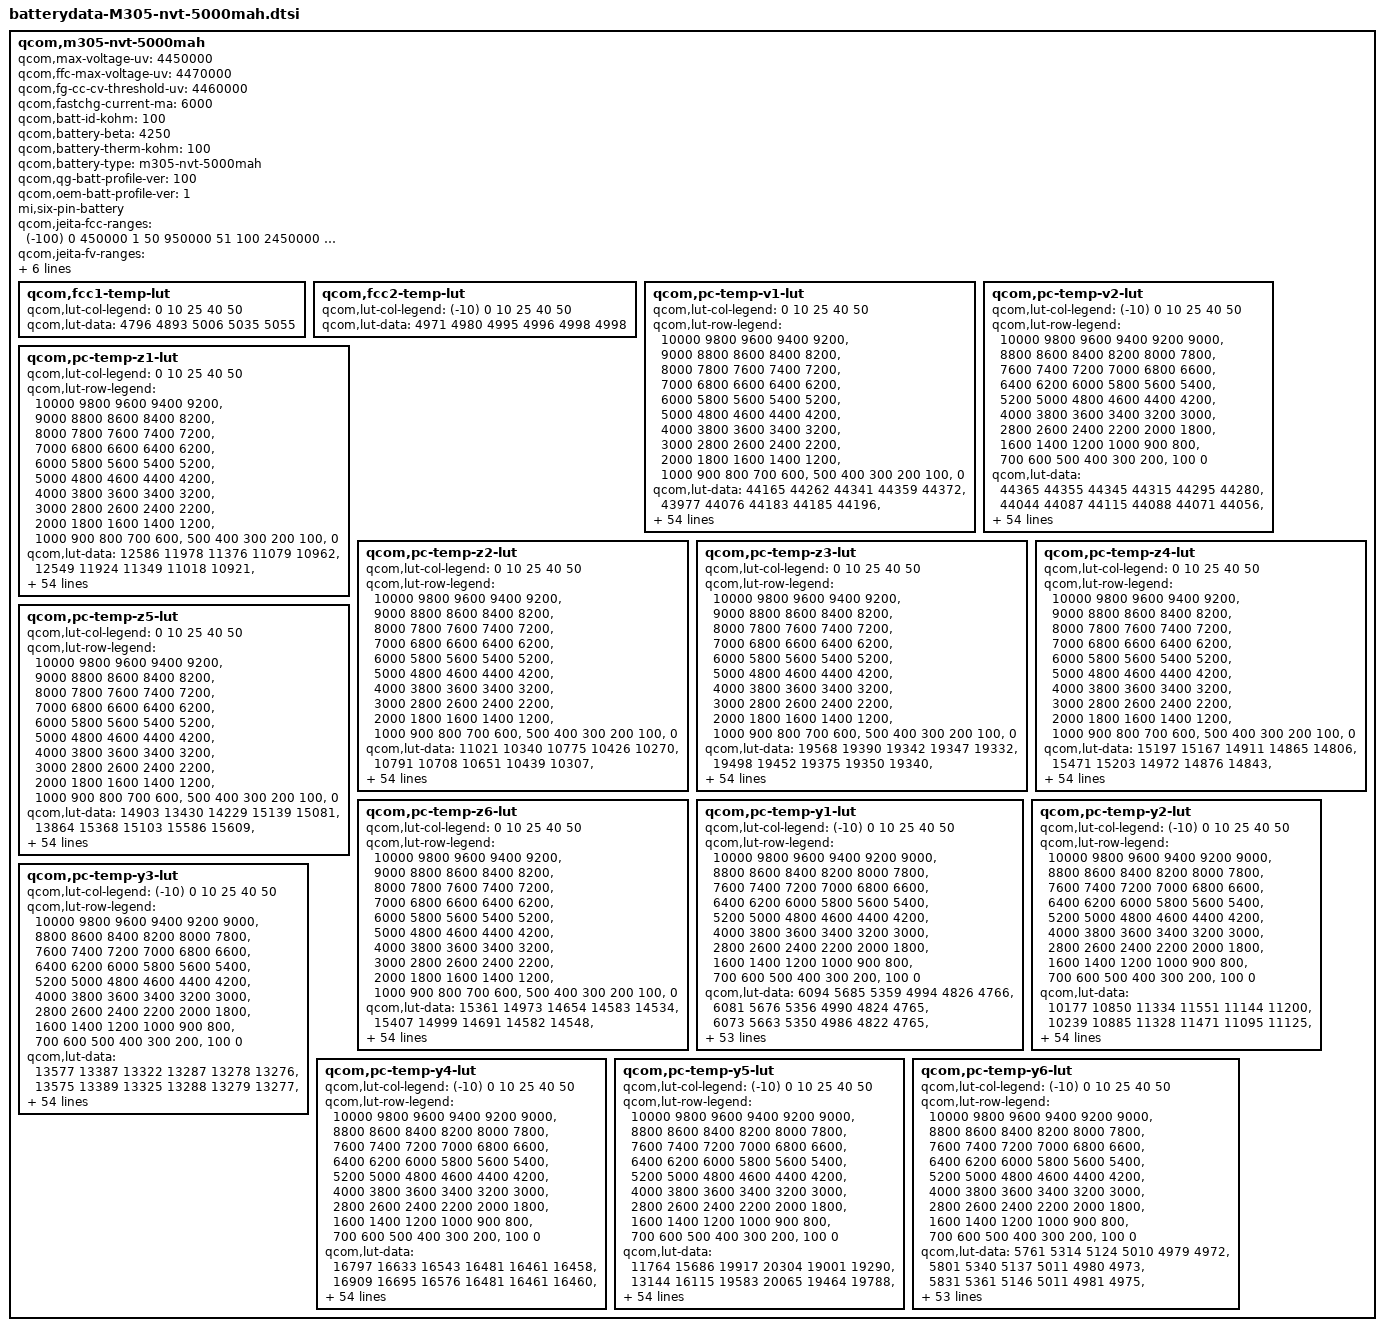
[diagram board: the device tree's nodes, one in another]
/*
 * Copyright (c) 2019, The Linux Foundation. All rights reserved.
 * Copyright (C) 2021 XiaoMi, Inc.
 *
 * This program is free software; you can redistribute it and/or modify
 * it under the terms of the GNU General Public License version 2 and
 * only version 2 as published by the Free Software Foundation.
 *
 * This program is distributed in the hope that it will be useful,
 * but WITHOUT ANY WARRANTY; without even the implied warranty of
 * MERCHANTABILITY or FITNESS FOR A PARTICULAR PURPOSE.  See the
 * GNU General Public License for more details.
 */
/* 4622819_LC_M700_ATL_5160mAH_PM7150B_averaged_Master_May26th2020 */

 qcom,m305-nvt-5000mah {
	qcom,max-voltage-uv = <4450000>;
	qcom,ffc-max-voltage-uv = <4470000>;
	qcom,fg-cc-cv-threshold-uv = <4460000>;
	qcom,fastchg-current-ma = <6000>;
	qcom,batt-id-kohm = <100>;
	qcom,battery-beta = <4250>;
	qcom,battery-therm-kohm = <100>;
	qcom,battery-type = "m305-nvt-5000mah";
	qcom,qg-batt-profile-ver = <100>;
	qcom,oem-batt-profile-ver = <1>;
	mi,six-pin-battery;

	qcom,jeita-fcc-ranges = <(-100)  0   450000
                                1   50   950000
				51  100  2450000
				101 150  3900000
				151 480  6000000
				481 580  2450000>;

	qcom,jeita-fv-ranges = <(-100)   0   4450000
                                1   50   4450000
				51  100  4450000
				101 150  4450000
				151 480  4470000
				481 580  4100000>;

	/* COOL = 15 degc, WARM = 48 degC */
	qcom,jeita-soft-thresholds = <0x4621 0x1de6>;
	/* COLD = -10 degC, HOT = 58 degC*/
	qcom,jeita-hard-thresholds = <0x6226 0x15f7>;
	/* COOL hys = 18 degC, WARM hys = 45 degC */
	qcom,jeita-soft-hys-thresholds = <0x4206 0x20b8>;
	qcom,jeita-soft-fcc-ua = <3900000 2450000>;
	qcom,jeita-soft-fv-uv = <4450000 4100000>;

	qcom,fcc1-temp-lut {
		qcom,lut-col-legend = <0 10 25 40 50>;
		qcom,lut-data = <4796 4893 5006 5035 5055>;
	};

	qcom,fcc2-temp-lut {
		qcom,lut-col-legend = <(-10) 0 10 25 40 50>;
		qcom,lut-data = <4971 4980 4995 4996 4998 4998>;
	};

	qcom,pc-temp-v1-lut {
		qcom,lut-col-legend = <0 10 25 40 50>;
		qcom,lut-row-legend = <10000 9800 9600 9400 9200>,
			<9000 8800 8600 8400 8200>,
			<8000 7800 7600 7400 7200>,
			<7000 6800 6600 6400 6200>,
			<6000 5800 5600 5400 5200>,
			<5000 4800 4600 4400 4200>,
			<4000 3800 3600 3400 3200>,
			<3000 2800 2600 2400 2200>,
			<2000 1800 1600 1400 1200>,
			<1000 900 800 700 600>,
			<500 400 300 200 100>,
			<0>;
		qcom,lut-data = <44165 44262 44341 44359 44372>,
			<43977 44076 44183 44185 44196>,
			<43767 43881 43986 44002 44014>,
			<43547 43680 43788 43811 43824>,
			<43319 43468 43583 43612 43623>,
			<43082 43240 43367 43401 43411>,
			<42843 43001 43137 43176 43190>,
			<42602 42761 42895 42936 42957>,
			<42360 42516 42651 42692 42718>,
			<42123 42271 42403 42446 42475>,
			<41889 42031 42157 42200 42227>,
			<41659 41793 41916 41959 41984>,
			<41434 41562 41677 41720 41741>,
			<41214 41334 41443 41485 41502>,
			<41001 41114 41214 41254 41270>,
			<40798 40907 40991 41028 41043>,
			<40597 40707 40778 40810 40826>,
			<40390 40509 40572 40600 40617>,
			<40184 40318 40375 40399 40416>,
			<39991 40120 40193 40218 40230>,
			<39821 39887 39993 40028 40040>,
			<39648 39616 39726 39782 39804>,
			<39434 39375 39434 39496 39524>,
			<39178 39178 39227 39276 39298>,
			<38972 39009 39078 39120 39138>,
			<38837 38884 38950 38986 39002>,
			<38731 38790 38833 38854 38867>,
			<38648 38703 38728 38732 38738>,
			<38583 38616 38626 38622 38623>,
			<38524 38534 38526 38523 38522>,
			<38467 38458 38435 38432 38430>,
			<38414 38385 38354 38348 38344>,
			<38364 38320 38281 38269 38265>,
			<38317 38265 38215 38196 38189>,
			<38274 38216 38158 38127 38117>,
			<38235 38170 38103 38061 38045>,
			<38200 38130 38051 37996 37969>,
			<38156 38085 37999 37932 37890>,
			<38080 38012 37928 37850 37798>,
			<37977 37909 37829 37744 37689>,
			<37864 37793 37715 37626 37567>,
			<37729 37661 37589 37499 37432>,
			<37577 37512 37446 37360 37286>,
			<37400 37337 37278 37200 37119>,
			<37272 37202 37146 37073 37003>,
			<37185 37128 37070 37004 36945>,
			<37164 37102 37050 36982 36925>,
			<37152 37085 37031 36966 36906>,
			<37111 37052 37002 36931 36862>,
			<36989 36928 36861 36765 36667>,
			<36621 36559 36490 36396 36294>,
			<36126 36069 36002 35912 35806>,
			<35490 35438 35371 35288 35176>,
			<34613 34564 34506 34428 34307>,
			<33199 33156 33113 33066 32918>,
			<30000 30000 30000 30000 30000>;
	};

	qcom,pc-temp-v2-lut {
		qcom,lut-col-legend = <(-10) 0 10 25 40 50>;
		qcom,lut-row-legend = <10000 9800 9600 9400 9200 9000>,
			<8800 8600 8400 8200 8000 7800>,
			<7600 7400 7200 7000 6800 6600>,
			<6400 6200 6000 5800 5600 5400>,
			<5200 5000 4800 4600 4400 4200>,
			<4000 3800 3600 3400 3200 3000>,
			<2800 2600 2400 2200 2000 1800>,
			<1600 1400 1200 1000 900 800>,
			<700 600 500 400 300 200>,
			<100 0>;
		qcom,lut-data = <44365 44355 44345 44315 44295 44280>,
			<44044 44087 44115 44088 44071 44056>,
			<43750 43835 43889 43865 43851 43836>,
			<43490 43603 43673 43649 43637 43623>,
			<43264 43392 43465 43439 43429 43417>,
			<43036 43175 43250 43223 43215 43204>,
			<42782 42934 43014 42989 42984 42974>,
			<42519 42683 42770 42746 42743 42735>,
			<42271 42432 42524 42501 42501 42494>,
			<42039 42180 42275 42254 42255 42249>,
			<41798 41931 42027 42008 42010 42005>,
			<41504 41688 41784 41767 41769 41764>,
			<41206 41450 41544 41528 41530 41525>,
			<41017 41222 41310 41293 41297 41291>,
			<40911 41004 41081 41062 41069 41062>,
			<40783 40792 40859 40839 40847 40839>,
			<40480 40593 40653 40627 40632 40626>,
			<40055 40395 40449 40421 40425 40420>,
			<39746 40159 40221 40219 40226 40223>,
			<39527 39867 39967 40025 40040 40039>,
			<39324 39584 39715 39815 39837 39839>,
			<39109 39346 39472 39555 39581 39584>,
			<38895 39130 39242 39281 39309 39315>,
			<38682 38939 39048 39071 39099 39106>,
			<38449 38768 38882 38903 38927 38934>,
			<38272 38612 38734 38757 38778 38785>,
			<38187 38471 38598 38626 38646 38653>,
			<38129 38341 38475 38510 38530 38535>,
			<38075 38216 38364 38403 38424 38425>,
			<38028 38087 38263 38304 38326 38323>,
			<37982 37987 38168 38212 38236 38230>,
			<37934 37929 38073 38125 38155 38149>,
			<37885 37886 37983 38044 38079 38072>,
			<37832 37848 37907 37970 37998 37988>,
			<37777 37818 37841 37903 37915 37896>,
			<37719 37782 37782 37833 37824 37797>,
			<37654 37736 37732 37746 37722 37683>,
			<37582 37676 37685 37653 37613 37562>,
			<37504 37600 37620 37563 37514 37458>,
			<37417 37495 37534 37477 37422 37368>,
			<37322 37375 37432 37383 37325 37272>,
			<37214 37244 37306 37269 37214 37156>,
			<37097 37108 37166 37144 37094 37030>,
			<36993 36988 37026 37006 36955 36888>,
			<36899 36888 36921 36917 36869 36811>,
			<36817 36798 36856 36878 36838 36783>,
			<36773 36736 36829 36863 36826 36768>,
			<36723 36655 36790 36839 36805 36744>,
			<36654 36548 36723 36788 36755 36676>,
			<36517 36367 36554 36604 36543 36397>,
			<36234 36077 36191 36189 36122 35956>,
			<35760 35632 35641 35647 35581 35391>,
			<35079 34982 34908 34939 34877 34643>,
			<34112 34036 33881 33943 33895 33601>,
			<32348 32327 32206 32341 32401 32072>,
			<27302 27182 27133 27142 28004 27330>;
	};

	qcom,pc-temp-z1-lut {
		qcom,lut-col-legend = <0 10 25 40 50>;
		qcom,lut-row-legend = <10000 9800 9600 9400 9200>,
			<9000 8800 8600 8400 8200>,
			<8000 7800 7600 7400 7200>,
			<7000 6800 6600 6400 6200>,
			<6000 5800 5600 5400 5200>,
			<5000 4800 4600 4400 4200>,
			<4000 3800 3600 3400 3200>,
			<3000 2800 2600 2400 2200>,
			<2000 1800 1600 1400 1200>,
			<1000 900 800 700 600>,
			<500 400 300 200 100>,
			<0>;
		qcom,lut-data = <12586 11978 11376 11079 10962>,
			<12549 11924 11349 11018 10921>,
			<12517 11890 11290 10993 10899>,
			<12487 11867 11256 10977 10884>,
			<12457 11845 11237 10965 10874>,
			<12428 11817 11220 10954 10866>,
			<12402 11788 11202 10944 10859>,
			<12377 11764 11185 10934 10852>,
			<12355 11744 11171 10927 10847>,
			<12342 11726 11160 10924 10845>,
			<12333 11707 11152 10921 10843>,
			<12324 11688 11148 10918 10842>,
			<12309 11681 11145 10916 10840>,
			<12292 11680 11143 10915 10839>,
			<12277 11679 11142 10914 10839>,
			<12255 11678 11141 10914 10839>,
			<12241 11675 11142 10914 10840>,
			<12242 11672 11142 10914 10841>,
			<12248 11670 11143 10914 10842>,
			<12255 11667 11144 10916 10844>,
			<12306 11667 11145 10917 10845>,
			<12358 11669 11146 10917 10846>,
			<12345 11670 11147 10917 10846>,
			<12285 11670 11148 10917 10846>,
			<12253 11670 11151 10918 10847>,
			<12255 11672 11154 10920 10850>,
			<12261 11680 11158 10922 10852>,
			<12265 11686 11162 10925 10854>,
			<12271 11687 11167 10928 10856>,
			<12276 11689 11171 10931 10859>,
			<12281 11692 11176 10934 10862>,
			<12288 11702 11182 10938 10865>,
			<12291 11712 11188 10942 10868>,
			<12297 11717 11193 10946 10871>,
			<12304 11722 11198 10950 10874>,
			<12306 11726 11204 10954 10878>,
			<12314 11732 11210 10958 10882>,
			<12318 11740 11216 10962 10885>,
			<12332 11749 11222 10966 10888>,
			<12352 11760 11229 10969 10891>,
			<12356 11766 11236 10973 10894>,
			<12352 11769 11243 10977 10897>,
			<12352 11773 11250 10980 10900>,
			<12362 11794 11255 10983 10901>,
			<12370 11817 11267 10988 10904>,
			<12393 11814 11276 10992 10905>,
			<12377 11813 11279 10990 10905>,
			<12399 11821 11279 10992 10907>,
			<12406 11821 11285 10994 10910>,
			<12418 11830 11295 10999 10913>,
			<12388 11832 11300 11005 10916>,
			<12401 11842 11313 11009 10922>,
			<12416 11850 11321 11017 10928>,
			<12454 11883 11337 11028 10939>,
			<12454 11883 11337 11028 10939>,
			<12454 11883 11337 11028 10939>;
	};

	qcom,pc-temp-z2-lut {
		qcom,lut-col-legend = <0 10 25 40 50>;
		qcom,lut-row-legend = <10000 9800 9600 9400 9200>,
			<9000 8800 8600 8400 8200>,
			<8000 7800 7600 7400 7200>,
			<7000 6800 6600 6400 6200>,
			<6000 5800 5600 5400 5200>,
			<5000 4800 4600 4400 4200>,
			<4000 3800 3600 3400 3200>,
			<3000 2800 2600 2400 2200>,
			<2000 1800 1600 1400 1200>,
			<1000 900 800 700 600>,
			<500 400 300 200 100>,
			<0>;
		qcom,lut-data = <11021 10340 10775 10426 10270>,
			<10791 10708 10651 10439 10307>,
			<10697 10779 10669 10457 10322>,
			<10637 10750 10670 10465 10328>,
			<10587 10710 10652 10462 10359>,
			<10546 10663 10627 10451 10409>,
			<10509 10607 10577 10428 10411>,
			<10472 10564 10508 10387 10359>,
			<10443 10528 10474 10363 10318>,
			<10426 10505 10454 10356 10307>,
			<10413 10499 10445 10352 10300>,
			<10408 10496 10449 10348 10298>,
			<10410 10497 10459 10336 10301>,
			<10414 10518 10471 10331 10303>,
			<10425 10552 10485 10339 10313>,
			<10456 10636 10497 10348 10327>,
			<10486 10802 10504 10349 10314>,
			<10501 10868 10511 10349 10253>,
			<10513 10758 10519 10347 10221>,
			<10520 10635 10535 10317 10231>,
			<10525 10634 10559 10288 10253>,
			<10530 10659 10613 10362 10306>,
			<10534 10671 10681 10555 10416>,
			<10540 10645 10684 10616 10463>,
			<10544 10608 10609 10501 10440>,
			<10546 10604 10555 10393 10414>,
			<10548 10623 10589 10495 10450>,
			<10550 10644 10656 10745 10561>,
			<10555 10661 10689 10813 10599>,
			<10560 10676 10707 10646 10455>,
			<10568 10682 10715 10465 10277>,
			<10578 10682 10687 10390 10193>,
			<10587 10680 10637 10338 10132>,
			<10595 10681 10616 10314 10118>,
			<10602 10683 10607 10299 10147>,
			<10611 10686 10604 10291 10194>,
			<10620 10693 10624 10311 10252>,
			<10632 10703 10669 10365 10328>,
			<10652 10725 10709 10438 10387>,
			<10676 10763 10750 10566 10430>,
			<10693 10783 10779 10658 10469>,
			<10704 10787 10791 10675 10515>,
			<10724 10794 10800 10682 10559>,
			<10780 10828 10809 10675 10609>,
			<11129 10996 10836 10642 10547>,
			<11189 11068 10838 10479 10360>,
			<11184 11046 10812 10472 10367>,
			<11228 11071 10791 10486 10394>,
			<11265 11080 10746 10582 10496>,
			<11215 11189 10860 10535 10452>,
			<11065 11264 10783 10327 10187>,
			<10883 11241 10688 10240 10130>,
			<10651 11299 10604 10192 10067>,
			<10371 11200 10551 10122 10005>,
			<10371 11200 10551 10122 10005>,
			<10371 11200 10551 10122 10005>;
	};

	qcom,pc-temp-z3-lut {
		qcom,lut-col-legend = <0 10 25 40 50>;
		qcom,lut-row-legend = <10000 9800 9600 9400 9200>,
			<9000 8800 8600 8400 8200>,
			<8000 7800 7600 7400 7200>,
			<7000 6800 6600 6400 6200>,
			<6000 5800 5600 5400 5200>,
			<5000 4800 4600 4400 4200>,
			<4000 3800 3600 3400 3200>,
			<3000 2800 2600 2400 2200>,
			<2000 1800 1600 1400 1200>,
			<1000 900 800 700 600>,
			<500 400 300 200 100>,
			<0>;
		qcom,lut-data = <19568 19390 19342 19347 19332>,
			<19498 19452 19375 19350 19340>,
			<19572 19487 19405 19370 19357>,
			<19628 19509 19424 19387 19375>,
			<19648 19524 19437 19396 19388>,
			<19660 19532 19445 19404 19399>,
			<19666 19538 19450 19411 19403>,
			<19668 19540 19453 19419 19405>,
			<19669 19539 19454 19421 19405>,
			<19667 19538 19450 19418 19403>,
			<19663 19535 19444 19413 19399>,
			<19658 19530 19438 19408 19396>,
			<19655 19523 19430 19401 19394>,
			<19650 19512 19424 19396 19391>,
			<19644 19503 19420 19393 19388>,
			<19633 19503 19417 19390 19384>,
			<19624 19508 19411 19387 19380>,
			<19619 19509 19405 19383 19374>,
			<19615 19497 19402 19379 19369>,
			<19614 19484 19398 19371 19363>,
			<19615 19489 19397 19364 19358>,
			<19617 19513 19404 19366 19358>,
			<19624 19527 19418 19372 19360>,
			<19641 19518 19418 19373 19360>,
			<19650 19504 19400 19359 19355>,
			<19647 19494 19386 19345 19350>,
			<19641 19486 19384 19363 19364>,
			<19635 19482 19383 19407 19405>,
			<19627 19485 19386 19421 19421>,
			<19621 19491 19408 19417 19414>,
			<19617 19497 19426 19411 19403>,
			<19614 19503 19428 19405 19394>,
			<19612 19506 19429 19397 19386>,
			<19610 19505 19428 19389 19376>,
			<19609 19502 19421 19380 19364>,
			<19607 19499 19413 19372 19355>,
			<19602 19495 19407 19365 19353>,
			<19598 19490 19402 19360 19352>,
			<19593 19486 19398 19358 19351>,
			<19587 19481 19395 19358 19348>,
			<19580 19477 19394 19358 19346>,
			<19572 19473 19394 19362 19352>,
			<19562 19469 19394 19368 19363>,
			<19547 19462 19393 19369 19370>,
			<19477 19435 19382 19366 19368>,
			<19461 19416 19372 19347 19347>,
			<19418 19416 19365 19344 19335>,
			<19306 19405 19364 19336 19329>,
			<19302 19403 19350 19329 19324>,
			<19301 19394 19350 19344 19335>,
			<19308 19385 19374 19365 19357>,
			<19304 19381 19379 19367 19359>,
			<19303 19349 19381 19362 19357>,
			<19304 19320 19355 19360 19358>,
			<19304 19320 19355 19360 19358>,
			<19304 19320 19355 19360 19358>;
	};

	qcom,pc-temp-z4-lut {
		qcom,lut-col-legend = <0 10 25 40 50>;
		qcom,lut-row-legend = <10000 9800 9600 9400 9200>,
			<9000 8800 8600 8400 8200>,
			<8000 7800 7600 7400 7200>,
			<7000 6800 6600 6400 6200>,
			<6000 5800 5600 5400 5200>,
			<5000 4800 4600 4400 4200>,
			<4000 3800 3600 3400 3200>,
			<3000 2800 2600 2400 2200>,
			<2000 1800 1600 1400 1200>,
			<1000 900 800 700 600>,
			<500 400 300 200 100>,
			<0>;
		qcom,lut-data = <15197 15167 14911 14865 14806>,
			<15471 15203 14972 14876 14843>,
			<15405 15195 14960 14867 14838>,
			<15317 15115 14941 14855 14830>,
			<15229 15029 14899 14832 14814>,
			<15132 14970 14855 14804 14789>,
			<15056 14919 14824 14780 14770>,
			<14998 14877 14797 14759 14752>,
			<14951 14843 14773 14742 14738>,
			<14911 14813 14749 14727 14726>,
			<14877 14787 14732 14716 14716>,
			<14848 14764 14726 14711 14710>,
			<14822 14751 14722 14707 14707>,
			<14800 14745 14717 14703 14703>,
			<14782 14740 14709 14698 14700>,
			<14765 14726 14703 14693 14696>,
			<14756 14706 14698 14688 14693>,
			<14759 14698 14695 14683 14689>,
			<14766 14706 14692 14680 14686>,
			<14767 14719 14688 14678 14683>,
			<14756 14733 14686 14676 14680>,
			<14744 14756 14716 14698 14698>,
			<14755 14783 14775 14759 14761>,
			<14802 14817 14808 14796 14791>,
			<14833 14848 14829 14813 14793>,
			<14839 14851 14838 14822 14794>,
			<14842 14842 14833 14798 14775>,
			<14841 14829 14819 14737 14719>,
			<14829 14813 14801 14708 14692>,
			<14815 14793 14767 14700 14689>,
			<14804 14777 14738 14694 14686>,
			<14793 14762 14723 14688 14683>,
			<14784 14752 14712 14684 14679>,
			<14778 14748 14709 14683 14677>,
			<14772 14745 14708 14684 14677>,
			<14765 14742 14707 14684 14676>,
			<14759 14739 14708 14685 14676>,
			<14754 14737 14709 14685 14675>,
			<14752 14738 14713 14688 14676>,
			<14751 14740 14722 14700 14691>,
			<14748 14741 14727 14710 14703>,
			<14738 14732 14721 14704 14697>,
			<14727 14720 14712 14696 14688>,
			<14718 14712 14709 14696 14688>,
			<14691 14686 14692 14684 14678>,
			<14680 14665 14669 14670 14663>,
			<14721 14657 14660 14663 14661>,
			<14837 14655 14644 14650 14645>,
			<14836 14650 14645 14636 14630>,
			<14834 14661 14657 14640 14650>,
			<14840 14685 14656 14651 14660>,
			<14850 14693 14655 14656 14663>,
			<14857 14731 14656 14664 14669>,
			<14865 14769 14686 14669 14669>,
			<14865 14769 14686 14669 14669>,
			<14865 14769 14686 14669 14669>;
	};

	qcom,pc-temp-z5-lut {
		qcom,lut-col-legend = <0 10 25 40 50>;
		qcom,lut-row-legend = <10000 9800 9600 9400 9200>,
			<9000 8800 8600 8400 8200>,
			<8000 7800 7600 7400 7200>,
			<7000 6800 6600 6400 6200>,
			<6000 5800 5600 5400 5200>,
			<5000 4800 4600 4400 4200>,
			<4000 3800 3600 3400 3200>,
			<3000 2800 2600 2400 2200>,
			<2000 1800 1600 1400 1200>,
			<1000 900 800 700 600>,
			<500 400 300 200 100>,
			<0>;
		qcom,lut-data = <14903 13430 14229 15139 15081>,
			<13864 15368 15103 15586 15609>,
			<15280 16599 16799 17152 17253>,
			<16598 17422 17904 18507 19060>,
			<17311 18099 18593 19248 20799>,
			<17859 18708 19200 19953 22471>,
			<18426 19267 19806 21076 23525>,
			<19032 19902 20402 22639 24188>,
			<19637 20616 21143 23922 24850>,
			<20252 21419 22234 24998 25700>,
			<20942 22490 22889 25706 26597>,
			<21760 23715 22768 25611 27408>,
			<22824 24398 22533 25158 28153>,
			<24045 24592 22579 24989 28894>,
			<25251 24856 23343 25687 29816>,
			<26607 26403 24054 26791 30593>,
			<27564 29531 24338 28005 30740>,
			<27784 30748 24539 29468 30655>,
			<27840 28672 24651 29906 30652>,
			<28166 26313 25345 28893 31129>,
			<30096 30848 26545 27877 31668>,
			<33506 48498 31002 28081 31218>,
			<39808 58178 37458 28754 29013>,
			<51275 50057 37560 28559 26212>,
			<57275 37272 28499 22622 21497>,
			<53842 31081 20968 17027 17525>,
			<47600 27275 19284 19162 20255>,
			<43224 25618 18296 24931 29239>,
			<39561 26058 18530 27520 33142>,
			<37504 27218 21383 28143 32759>,
			<37542 28988 24903 28576 32188>,
			<37870 32747 28309 29161 32026>,
			<38400 36459 31621 29782 31568>,
			<40019 38827 33334 29899 30824>,
			<41968 40725 34448 29502 28893>,
			<43049 41496 34940 29095 27360>,
			<43783 41599 34636 28885 28330>,
			<44460 41417 33878 28614 30608>,
			<45308 40856 32786 28162 30906>,
			<46046 39768 30790 26839 27117>,
			<45902 38711 29229 25900 23968>,
			<43780 37746 28640 26042 25522>,
			<42280 36863 28247 26348 29028>,
			<41638 36000 27877 26689 32846>,
			<36162 36680 27734 26703 32907>,
			<32596 34052 27976 21901 23332>,
			<26661 34608 26535 21856 19758>,
			<12967 29427 30212 22016 21596>,
			<12877 29456 25588 24980 25982>,
			<12932 25788 23052 32830 30604>,
			<13066 20545 24485 27015 24918>,
			<12786 18826 24290 24167 22687>,
			<12580 15552 23435 19871 19339>,
			<12399 13309 16331 17649 17321>,
			<12399 13309 16331 17649 17321>,
			<12399 13309 16331 17649 17321>;
	};

	qcom,pc-temp-z6-lut {
		qcom,lut-col-legend = <0 10 25 40 50>;
		qcom,lut-row-legend = <10000 9800 9600 9400 9200>,
			<9000 8800 8600 8400 8200>,
			<8000 7800 7600 7400 7200>,
			<7000 6800 6600 6400 6200>,
			<6000 5800 5600 5400 5200>,
			<5000 4800 4600 4400 4200>,
			<4000 3800 3600 3400 3200>,
			<3000 2800 2600 2400 2200>,
			<2000 1800 1600 1400 1200>,
			<1000 900 800 700 600>,
			<500 400 300 200 100>,
			<0>;
		qcom,lut-data = <15361 14973 14654 14583 14534>,
			<15407 14999 14691 14582 14548>,
			<15378 14997 14692 14584 14551>,
			<15336 14960 14688 14584 14553>,
			<15286 14918 14673 14578 14551>,
			<15223 14886 14655 14569 14546>,
			<15174 14857 14642 14562 14541>,
			<15136 14831 14629 14555 14534>,
			<15103 14809 14617 14549 14527>,
			<15073 14789 14603 14540 14520>,
			<15046 14770 14592 14532 14514>,
			<15023 14753 14584 14526 14509>,
			<15002 14740 14578 14521 14506>,
			<14983 14731 14572 14516 14503>,
			<14967 14724 14566 14512 14499>,
			<14949 14717 14561 14507 14496>,
			<14939 14711 14556 14503 14491>,
			<14938 14707 14551 14499 14487>,
			<14938 14705 14548 14495 14482>,
			<14937 14703 14545 14489 14477>,
			<14933 14709 14543 14485 14473>,
			<14930 14733 14562 14497 14481>,
			<14938 14752 14596 14529 14509>,
			<14970 14762 14604 14540 14522>,
			<14990 14769 14605 14540 14521>,
			<14990 14768 14605 14539 14519>,
			<14990 14762 14602 14538 14518>,
			<14989 14754 14596 14535 14517>,
			<14982 14750 14592 14532 14514>,
			<14974 14746 14589 14527 14510>,
			<14968 14743 14587 14522 14504>,
			<14964 14741 14584 14517 14499>,
			<14961 14740 14580 14512 14493>,
			<14959 14738 14577 14507 14488>,
			<14958 14737 14574 14503 14481>,
			<14956 14736 14571 14499 14477>,
			<14954 14734 14569 14496 14475>,
			<14954 14733 14568 14494 14474>,
			<14955 14733 14568 14494 14474>,
			<14957 14735 14572 14499 14478>,
			<14957 14736 14574 14504 14482>,
			<14955 14733 14573 14504 14484>,
			<14953 14730 14570 14504 14486>,
			<14949 14728 14569 14505 14490>,
			<14916 14712 14559 14499 14485>,
			<14909 14696 14545 14483 14467>,
			<14904 14691 14538 14479 14460>,
			<14899 14686 14532 14469 14450>,
			<14899 14686 14525 14459 14441>,
			<14905 14690 14532 14469 14455>,
			<14917 14701 14547 14487 14474>,
			<14926 14706 14551 14493 14479>,
			<14937 14712 14555 14496 14483>,
			<14955 14722 14559 14500 14486>,
			<14955 14722 14559 14500 14486>,
			<14955 14722 14559 14500 14486>;
	};

	qcom,pc-temp-y1-lut {
		qcom,lut-col-legend = <(-10) 0 10 25 40 50>;
		qcom,lut-row-legend = <10000 9800 9600 9400 9200 9000>,
			<8800 8600 8400 8200 8000 7800>,
			<7600 7400 7200 7000 6800 6600>,
			<6400 6200 6000 5800 5600 5400>,
			<5200 5000 4800 4600 4400 4200>,
			<4000 3800 3600 3400 3200 3000>,
			<2800 2600 2400 2200 2000 1800>,
			<1600 1400 1200 1000 900 800>,
			<700 600 500 400 300 200>,
			<100 0>;
		qcom,lut-data = <6094 5685 5359 4994 4826 4766>,
			<6081 5676 5356 4990 4824 4765>,
			<6073 5663 5350 4986 4822 4765>,
			<6069 5650 5343 4981 4820 4765>,
			<6068 5639 5336 4977 4818 4764>,
			<6069 5634 5333 4973 4816 4763>,
			<6073 5635 5329 4968 4815 4762>,
			<6080 5636 5324 4963 4813 4761>,
			<6081 5636 5321 4960 4812 4760>,
			<6073 5633 5314 4956 4811 4759>,
			<6068 5631 5307 4954 4809 4758>,
			<6079 5631 5301 4951 4808 4758>,
			<6098 5631 5294 4948 4806 4757>,
			<6103 5632 5290 4946 4805 4757>,
			<6096 5638 5287 4945 4804 4756>,
			<6091 5643 5284 4944 4803 4756>,
			<6095 5641 5282 4944 4803 4755>,
			<6100 5637 5281 4944 4802 4755>,
			<6100 5635 5281 4944 4802 4755>,
			<6097 5639 5284 4945 4803 4755>,
			<6094 5643 5287 4946 4803 4756>,
			<6093 5641 5287 4948 4804 4757>,
			<6092 5637 5286 4950 4805 4758>,
			<6092 5641 5285 4952 4807 4759>,
			<6098 5650 5286 4955 4808 4760>,
			<6103 5657 5286 4958 4809 4761>,
			<6105 5657 5291 4960 4811 4762>,
			<6107 5655 5298 4963 4813 4764>,
			<6103 5655 5301 4966 4815 4765>,
			<6088 5656 5302 4971 4818 4766>,
			<6074 5656 5305 4975 4820 4768>,
			<6072 5654 5311 4980 4823 4771>,
			<6074 5651 5319 4984 4825 4774>,
			<6075 5652 5325 4989 4828 4776>,
			<6073 5663 5329 4995 4831 4777>,
			<6069 5673 5332 5000 4833 4779>,
			<6069 5666 5336 5003 4835 4780>,
			<6073 5652 5341 5007 4837 4782>,
			<6073 5648 5345 5010 4839 4784>,
			<6057 5651 5350 5013 4841 4786>,
			<6042 5655 5355 5017 4843 4788>,
			<6048 5656 5359 5021 4845 4789>,
			<6060 5656 5364 5027 4846 4791>,
			<6056 5654 5395 5034 4851 4794>,
			<6053 5654 5400 5045 4854 4796>,
			<6074 5662 5395 5044 4855 4797>,
			<6073 5675 5396 5046 4855 4797>,
			<6062 5679 5387 5047 4854 4796>,
			<6076 5676 5392 5042 4853 4797>,
			<6083 5669 5401 5040 4854 4798>,
			<6098 5683 5403 5048 4857 4800>,
			<6113 5679 5409 5058 4861 4804>,
			<6120 5679 5417 5072 4866 4809>,
			<6195 5721 5405 5087 4873 4817>,
			<6195 5721 5405 5087 4873 4817>,
			<6195 5721 5405 5087 4873 4817>;
	};

	qcom,pc-temp-y2-lut {
		qcom,lut-col-legend = <(-10) 0 10 25 40 50>;
		qcom,lut-row-legend = <10000 9800 9600 9400 9200 9000>,
			<8800 8600 8400 8200 8000 7800>,
			<7600 7400 7200 7000 6800 6600>,
			<6400 6200 6000 5800 5600 5400>,
			<5200 5000 4800 4600 4400 4200>,
			<4000 3800 3600 3400 3200 3000>,
			<2800 2600 2400 2200 2000 1800>,
			<1600 1400 1200 1000 900 800>,
			<700 600 500 400 300 200>,
			<100 0>;
		qcom,lut-data = <10177 10850 11334 11551 11144 11200>,
			<10239 10885 11328 11471 11095 11125>,
			<10340 10939 11318 11387 11040 11040>,
			<10450 10996 11302 11306 10987 10958>,
			<10542 11042 11284 11237 10941 10889>,
			<10589 11062 11262 11190 10908 10845>,
			<10598 11058 11233 11159 10884 10824>,
			<10604 11051 11202 11137 10865 10809>,
			<10620 11051 11189 11128 10851 10789>,
			<10679 11060 11180 11123 10829 10761>,
			<10730 11066 11177 11120 10815 10740>,
			<10767 11046 11187 11121 10811 10730>,
			<10811 11011 11210 11126 10806 10723>,
			<10827 11034 11234 11135 10813 10718>,
			<10841 11225 11264 11157 10861 10712>,
			<10864 11362 11303 11189 10910 10709>,
			<10944 11334 11380 11243 10936 10722>,
			<11078 11285 11465 11322 10961 10755>,
			<11163 11281 11483 11413 11020 10813>,
			<11227 11333 11481 11538 11157 10947>,
			<11261 11373 11480 11605 11239 11037>,
			<11177 11373 11486 11540 11205 11053>,
			<10952 11369 11495 11436 11148 11063>,
			<10654 11371 11502 11417 11125 11070>,
			<10098 11381 11510 11430 11115 11075>,
			<9705 11388 11521 11447 11116 11082>,
			<9689 11373 11543 11468 11160 11096>,
			<9684 11343 11572 11497 11235 11119>,
			<9680 11338 11594 11530 11301 11156>,
			<9676 11366 11613 11579 11382 11228>,
			<9673 11388 11623 11620 11443 11288>,
			<9671 11357 11615 11646 11469 11322>,
			<9668 11279 11601 11667 11488 11349>,
			<9666 11206 11591 11680 11508 11378>,
			<9665 11142 11585 11691 11529 11435>,
			<9664 11058 11575 11696 11540 11469>,
			<9663 10840 11546 11676 11508 11396>,
			<9662 10498 11495 11634 11451 11272>,
			<9662 10276 11436 11596 11412 11219>,
			<9662 9954 11363 11560 11360 11187>,
			<9661 9712 11277 11527 11317 11172>,
			<9661 9686 11176 11505 11298 11152>,
			<9661 9676 11064 11480 11277 11115>,
			<9661 9671 10951 11420 11145 11022>,
			<9660 9667 10829 11330 11021 10881>,
			<9660 9666 10834 11257 11009 10809>,
			<9659 9665 10836 11269 11030 10840>,
			<9659 9664 10785 11266 11060 10848>,
			<9658 9663 10772 11255 11044 10841>,
			<9657 9661 10744 11256 11034 10838>,
			<9656 9660 10674 11180 10889 10773>,
			<9653 9658 10508 11080 10817 10683>,
			<9651 9656 10114 10993 10743 10579>,
			<9649 9652 9713 10888 10652 10439>,
			<9649 9652 9713 10888 10652 10439>,
			<9649 9652 9713 10888 10652 10439>;
	};

	qcom,pc-temp-y3-lut {
		qcom,lut-col-legend = <(-10) 0 10 25 40 50>;
		qcom,lut-row-legend = <10000 9800 9600 9400 9200 9000>,
			<8800 8600 8400 8200 8000 7800>,
			<7600 7400 7200 7000 6800 6600>,
			<6400 6200 6000 5800 5600 5400>,
			<5200 5000 4800 4600 4400 4200>,
			<4000 3800 3600 3400 3200 3000>,
			<2800 2600 2400 2200 2000 1800>,
			<1600 1400 1200 1000 900 800>,
			<700 600 500 400 300 200>,
			<100 0>;
		qcom,lut-data = <13577 13387 13322 13287 13278 13276>,
			<13575 13389 13325 13288 13279 13277>,
			<13572 13392 13327 13290 13281 13279>,
			<13569 13395 13329 13292 13282 13280>,
			<13567 13397 13331 13293 13284 13281>,
			<13565 13398 13333 13294 13285 13282>,
			<13563 13399 13334 13295 13285 13282>,
			<13562 13399 13336 13296 13285 13283>,
			<13562 13400 13337 13296 13286 13284>,
			<13563 13400 13338 13297 13286 13285>,
			<13562 13401 13338 13297 13287 13285>,
			<13520 13400 13338 13298 13288 13286>,
			<13449 13398 13337 13298 13288 13286>,
			<13434 13393 13336 13298 13289 13287>,
			<13451 13380 13334 13297 13290 13287>,
			<13464 13371 13332 13297 13291 13287>,
			<13457 13374 13330 13299 13292 13288>,
			<13441 13379 13328 13302 13293 13290>,
			<13427 13378 13326 13303 13294 13292>,
			<13414 13369 13325 13303 13295 13293>,
			<13403 13359 13323 13302 13296 13294>,
			<13394 13354 13320 13298 13292 13290>,
			<13386 13349 13316 13293 13285 13284>,
			<13379 13345 13314 13290 13282 13281>,
			<13369 13341 13312 13289 13281 13280>,
			<13364 13338 13311 13288 13281 13280>,
			<13369 13335 13310 13287 13280 13280>,
			<13383 13331 13309 13286 13280 13281>,
			<13402 13327 13308 13287 13280 13281>,
			<13430 13322 13308 13288 13280 13279>,
			<13464 13318 13307 13288 13280 13278>,
			<13502 13319 13306 13288 13281 13278>,
			<13546 13321 13304 13286 13281 13279>,
			<13594 13324 13304 13286 13281 13280>,
			<13652 13331 13305 13287 13281 13281>,
			<13711 13340 13306 13287 13281 13282>,
			<13770 13346 13308 13287 13281 13281>,
			<13827 13353 13310 13286 13280 13280>,
			<13879 13363 13311 13286 13280 13280>,
			<13927 13382 13313 13287 13282 13281>,
			<13968 13406 13314 13287 13283 13282>,
			<13996 13433 13316 13288 13283 13282>,
			<14019 13469 13318 13288 13284 13281>,
			<14051 13528 13321 13288 13281 13279>,
			<14092 13608 13327 13291 13282 13281>,
			<14108 13627 13328 13294 13289 13287>,
			<14110 13640 13334 13298 13292 13288>,
			<14190 13699 13342 13302 13293 13289>,
			<14284 13758 13352 13305 13294 13289>,
			<14393 13818 13358 13303 13290 13285>,
			<14561 13905 13361 13298 13287 13285>,
			<14995 14044 13369 13302 13289 13287>,
			<16234 14283 13396 13309 13295 13291>,
			<19267 15015 13522 13318 13303 13303>,
			<19267 15015 13522 13318 13303 13303>,
			<19267 15015 13522 13318 13303 13303>;
	};

	qcom,pc-temp-y4-lut {
		qcom,lut-col-legend = <(-10) 0 10 25 40 50>;
		qcom,lut-row-legend = <10000 9800 9600 9400 9200 9000>,
			<8800 8600 8400 8200 8000 7800>,
			<7600 7400 7200 7000 6800 6600>,
			<6400 6200 6000 5800 5600 5400>,
			<5200 5000 4800 4600 4400 4200>,
			<4000 3800 3600 3400 3200 3000>,
			<2800 2600 2400 2200 2000 1800>,
			<1600 1400 1200 1000 900 800>,
			<700 600 500 400 300 200>,
			<100 0>;
		qcom,lut-data = <16797 16633 16543 16481 16461 16458>,
			<16909 16695 16576 16481 16461 16460>,
			<17046 16778 16609 16482 16461 16462>,
			<17179 16861 16636 16482 16461 16463>,
			<17281 16926 16655 16482 16462 16464>,
			<17322 16952 16663 16483 16462 16465>,
			<17307 16946 16657 16483 16463 16464>,
			<17278 16931 16646 16484 16464 16464>,
			<17256 16918 16639 16485 16466 16463>,
			<17237 16902 16633 16489 16467 16464>,
			<17228 16893 16630 16493 16470 16465>,
			<17269 16894 16632 16497 16473 16467>,
			<17351 16897 16638 16503 16477 16469>,
			<17404 16911 16647 16510 16481 16473>,
			<17445 16971 16663 16521 16485 16477>,
			<17467 17014 16684 16533 16489 16482>,
			<17345 17010 16719 16545 16496 16486>,
			<17108 16998 16756 16557 16504 16491>,
			<17009 16972 16756 16574 16519 16501>,
			<16981 16882 16716 16602 16545 16523>,
			<16953 16794 16669 16617 16560 16535>,
			<16897 16749 16624 16579 16538 16519>,
			<16825 16714 16581 16516 16500 16491>,
			<16770 16687 16561 16491 16481 16476>,
			<16720 16665 16550 16481 16469 16466>,
			<16692 16645 16543 16476 16464 16462>,
			<16695 16624 16541 16479 16466 16462>,
			<16704 16604 16539 16486 16470 16462>,
			<16708 16580 16540 16491 16474 16465>,
			<16708 16547 16543 16496 16481 16473>,
			<16708 16527 16544 16502 16490 16482>,
			<16713 16533 16540 16508 16501 16493>,
			<16722 16550 16532 16515 16511 16502>,
			<16729 16567 16525 16520 16513 16503>,
			<16735 16585 16519 16525 16511 16502>,
			<16741 16605 16516 16527 16508 16500>,
			<16748 16630 16523 16513 16496 16491>,
			<16754 16658 16538 16490 16481 16479>,
			<16756 16676 16548 16484 16476 16478>,
			<16754 16690 16555 16482 16475 16483>,
			<16751 16699 16562 16482 16475 16486>,
			<16744 16701 16569 16483 16476 16485>,
			<16734 16700 16575 16486 16476 16483>,
			<16734 16699 16579 16478 16457 16454>,
			<16738 16712 16589 16478 16454 16453>,
			<16740 16729 16582 16489 16479 16498>,
			<16741 16746 16599 16506 16508 16532>,
			<16762 16792 16633 16533 16541 16565>,
			<16787 16849 16682 16565 16567 16577>,
			<16801 16902 16713 16548 16514 16492>,
			<16789 16933 16695 16497 16472 16475>,
			<16807 16935 16690 16503 16474 16475>,
			<17062 16940 16741 16518 16475 16475>,
			<18330 17188 16859 16552 16493 16498>,
			<18330 17188 16859 16552 16493 16498>,
			<18330 17188 16859 16552 16493 16498>;
	};

	qcom,pc-temp-y5-lut {
		qcom,lut-col-legend = <(-10) 0 10 25 40 50>;
		qcom,lut-row-legend = <10000 9800 9600 9400 9200 9000>,
			<8800 8600 8400 8200 8000 7800>,
			<7600 7400 7200 7000 6800 6600>,
			<6400 6200 6000 5800 5600 5400>,
			<5200 5000 4800 4600 4400 4200>,
			<4000 3800 3600 3400 3200 3000>,
			<2800 2600 2400 2200 2000 1800>,
			<1600 1400 1200 1000 900 800>,
			<700 600 500 400 300 200>,
			<100 0>;
		qcom,lut-data = <11764 15686 19917 20304 19001 19290>,
			<13144 16115 19583 20065 19464 19788>,
			<14517 16546 19147 19752 19666 20088>,
			<15799 16953 18710 19385 19670 20219>,
			<16907 17309 18373 18986 19536 20211>,
			<17753 17588 18237 18576 19328 20094>,
			<18343 17823 18291 18135 18777 19799>,
			<18812 18007 18376 17659 17978 19387>,
			<19313 18064 18355 17179 17443 19045>,
			<20056 18061 18109 16680 16981 18672>,
			<20488 18023 17772 16223 16565 18256>,
			<18619 17897 17260 15856 16165 17786>,
			<15361 17657 16609 15506 15808 17268>,
			<15169 17242 16108 15032 15633 16688>,
			<19106 16219 15628 14346 15654 15933>,
			<22061 15552 15395 13977 15701 15542>,
			<21467 17717 15694 14123 15491 15696>,
			<20316 21497 16420 14505 15204 15976>,
			<20160 22351 17539 15187 15316 16155>,
			<21289 22087 19727 16779 15811 16364>,
			<22538 21891 21438 18472 16497 16650>,
			<23373 22075 22186 20098 17798 17904>,
			<24074 22494 22667 21472 19208 19610>,
			<23535 22832 22732 21625 19425 20033>,
			<17685 23088 22673 21081 19176 20119>,
			<12782 23401 22617 20395 18817 20150>,
			<12552 24093 22558 19552 18069 19766>,
			<12479 24937 22514 18743 17157 18923>,
			<12496 24661 22656 18722 16822 17895>,
			<12802 20871 23209 19420 16670 16358>,
			<13125 17583 23636 19889 16627 15519>,
			<13273 17004 23818 19622 16792 15730>,
			<13434 16654 24004 19195 17146 16249>,
			<13612 16756 24079 19360 17675 17137>,
			<13897 18246 24154 20812 18691 19019>,
			<14148 19594 24188 21952 19684 20352>,
			<14248 19558 23733 22222 20432 20637>,
			<14310 19003 22755 22381 21107 20827>,
			<14390 18429 21768 22257 21667 21398>,
			<14540 16889 20627 21366 22186 22934>,
			<14651 15416 19595 20520 22707 24113>,
			<14429 14829 18699 20112 23382 24868>,
			<13947 14488 18150 19838 23792 25386>,
			<13734 14438 18088 19649 21058 20758>,
			<13646 14363 17816 19050 18473 18072>,
			<13661 14345 17792 18313 18656 16956>,
			<13609 14546 18096 18895 18049 16027>,
			<13802 15313 18219 18902 17422 15665>,
			<14332 16686 19146 19115 17201 15611>,
			<14463 17643 20232 19306 16701 16298>,
			<14301 17863 19931 19803 17410 16330>,
			<13463 17059 18350 20377 17207 16052>,
			<11693 14830 16010 21458 19596 16465>,
			<10081 11922 13844 22760 24609 25359>,
			<10081 11922 13844 22760 24609 25359>,
			<10081 11922 13844 22760 24609 25359>;
	};

	qcom,pc-temp-y6-lut {
		qcom,lut-col-legend = <(-10) 0 10 25 40 50>;
		qcom,lut-row-legend = <10000 9800 9600 9400 9200 9000>,
			<8800 8600 8400 8200 8000 7800>,
			<7600 7400 7200 7000 6800 6600>,
			<6400 6200 6000 5800 5600 5400>,
			<5200 5000 4800 4600 4400 4200>,
			<4000 3800 3600 3400 3200 3000>,
			<2800 2600 2400 2200 2000 1800>,
			<1600 1400 1200 1000 900 800>,
			<700 600 500 400 300 200>,
			<100 0>;
		qcom,lut-data = <5761 5314 5124 5010 4979 4972>,
			<5801 5340 5137 5011 4980 4973>,
			<5831 5361 5146 5011 4981 4975>,
			<5850 5377 5152 5012 4982 4976>,
			<5861 5387 5154 5012 4983 4977>,
			<5865 5390 5155 5013 4984 4978>,
			<5857 5386 5153 5013 4985 4978>,
			<5842 5377 5148 5013 4985 4979>,
			<5832 5370 5144 5014 4986 4979>,
			<5825 5363 5141 5015 4987 4980>,
			<5817 5357 5139 5016 4988 4981>,
			<5800 5353 5138 5017 4989 4982>,
			<5780 5350 5137 5019 4990 4983>,
			<5780 5350 5137 5021 4992 4984>,
			<5807 5357 5139 5023 4994 4985>,
			<5828 5361 5143 5026 4996 4986>,
			<5794 5362 5150 5031 4999 4989>,
			<5726 5361 5159 5036 5002 4991>,
			<5696 5356 5158 5042 5006 4996>,
			<5687 5325 5145 5049 5014 5003>,
			<5679 5294 5130 5053 5019 5007>,
			<5666 5279 5115 5040 5009 4999>,
			<5651 5267 5101 5018 4993 4986>,
			<5637 5260 5094 5009 4986 4979>,
			<5621 5254 5090 5005 4982 4976>,
			<5612 5250 5088 5004 4980 4975>,
			<5625 5246 5088 5005 4980 4975>,
			<5659 5243 5088 5006 4982 4975>,
			<5692 5240 5089 5008 4983 4976>,
			<5725 5235 5091 5011 4985 4978>,
			<5762 5232 5093 5013 4988 4980>,
			<5803 5240 5092 5015 4992 4983>,
			<5849 5260 5091 5017 4995 4986>,
			<5898 5283 5091 5019 4995 4987>,
			<5951 5312 5092 5021 4995 4988>,
			<6004 5345 5094 5022 4995 4988>,
			<6054 5381 5100 5019 4992 4985>,
			<6102 5420 5109 5012 4987 4981>,
			<6143 5461 5118 5011 4986 4980>,
			<6179 5503 5127 5012 4987 4983>,
			<6210 5549 5138 5012 4988 4985>,
			<6233 5598 5152 5014 4989 4985>,
			<6253 5654 5169 5016 4989 4984>,
			<6280 5721 5189 5015 4983 4975>,
			<6320 5806 5216 5018 4983 4976>,
			<6341 5835 5209 5025 4995 4994>,
			<6348 5854 5226 5033 5006 5005>,
			<6423 5922 5250 5043 5016 5015>,
			<6508 5994 5279 5054 5024 5019>,
			<6609 6067 5299 5047 5006 4992>,
			<6756 6155 5309 5031 4992 4987>,
			<7149 6281 5351 5037 4995 4989>,
			<8257 6493 5456 5049 5001 4993>,
			<10800 7192 5647 5069 5013 5010>,
			<10800 7192 5647 5069 5013 5010>,
			<10800 7192 5647 5069 5013 5010>;
	};

};
